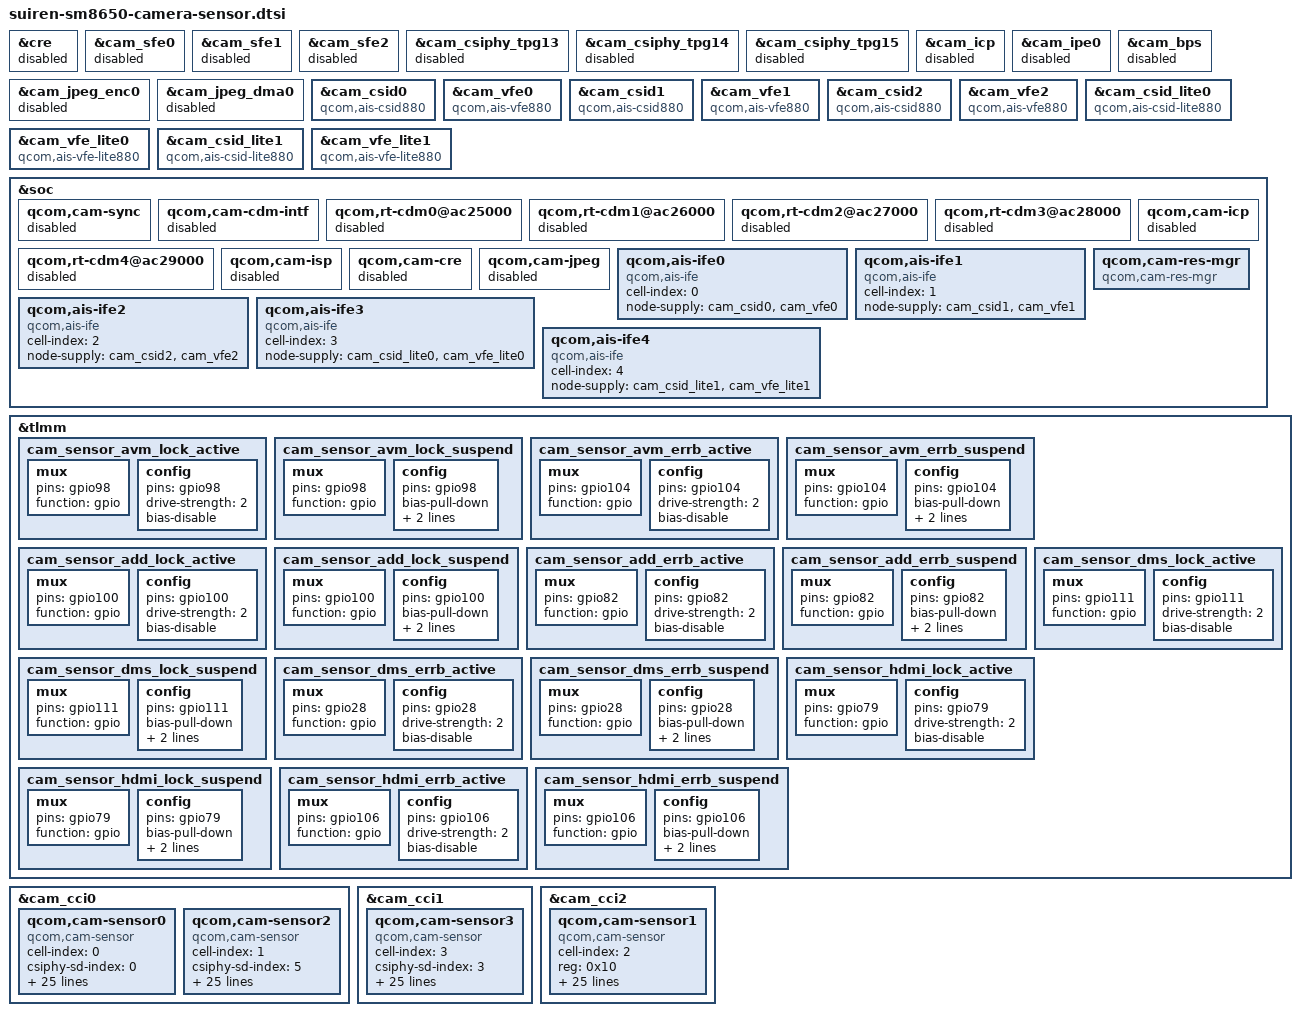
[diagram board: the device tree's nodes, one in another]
#include <dt-bindings/msm-camera.h>

/*Overlay to use AIS and disable unused devices*/
&cre {
	status = "disabled";
};

&cam_sfe0 {
	status = "disabled";
};

&cam_sfe1 {
	status = "disabled";
};

&cam_sfe2 {
	status = "disabled";
};

&cam_csiphy_tpg13 {
	status = "disabled";
};

&cam_csiphy_tpg14 {
	status = "disabled";
};

&cam_csiphy_tpg15 {
	status = "disabled";
};

&cam_icp {
	status = "disabled";
};

&cam_ipe0 {
	status = "disabled";
};

&cam_bps {
	status = "disabled";
};

&cam_jpeg_enc0 {
	status = "disabled";
};

&cam_jpeg_dma0 {
	status = "disabled";
};

&cam_csid0 {
	compatible = "qcom,ais-csid880";
};

&cam_vfe0 {
	compatible = "qcom,ais-vfe880";
};

&cam_csid1 {
	compatible = "qcom,ais-csid880";
};

&cam_vfe1 {
	compatible = "qcom,ais-vfe880";
};

&cam_csid2 {
	compatible = "qcom,ais-csid880";
};

&cam_vfe2 {
	compatible = "qcom,ais-vfe880";
};

&cam_csid_lite0 {
	compatible = "qcom,ais-csid-lite880";
};

&cam_vfe_lite0 {
	compatible = "qcom,ais-vfe-lite880";
};

&cam_csid_lite1 {
	compatible = "qcom,ais-csid-lite880";
};

&cam_vfe_lite1 {
	compatible = "qcom,ais-vfe-lite880";
};

&soc {
	qcom,cam-sync {
		status = "disabled";
	};

	qcom,cam-cdm-intf {
		status = "disabled";
	};

	qcom,rt-cdm0@ac25000 {
		status = "disabled";
	};

	qcom,rt-cdm1@ac26000 {
		status = "disabled";
	};

	qcom,rt-cdm2@ac27000 {
		status = "disabled";
	};

	qcom,rt-cdm3@ac28000 {
		status = "disabled";
	};

	qcom,rt-cdm4@ac29000 {
		status = "disabled";
	};

	qcom,cam-icp {
		status = "disabled";
	};

	qcom,cam-isp {
		status = "disabled";
	};

	qcom,cam-cre {
		status = "disabled";
	};

	qcom,cam-jpeg {
		status = "disabled";
	};

	qcom,ais-ife0 {
		compatible = "qcom,ais-ife";
		cell-index = <0>;
		status = "ok";
		node-supply=<&cam_csid0 &cam_vfe0>;
	};

	qcom,ais-ife1 {
		compatible = "qcom,ais-ife";
		cell-index = <1>;
		status = "ok";
		node-supply=<&cam_csid1 &cam_vfe1>;
	};

	qcom,ais-ife2 {
		compatible = "qcom,ais-ife";
		cell-index = <2>;
		status = "ok";
		node-supply=<&cam_csid2 &cam_vfe2>;
	};

	qcom,ais-ife3 {
		compatible = "qcom,ais-ife";
		cell-index = <3>;
		status = "ok";
		node-supply=<&cam_csid_lite0 &cam_vfe_lite0>;
	};

	qcom,ais-ife4 {
		compatible = "qcom,ais-ife";
		cell-index = <4>;
		status = "ok";
		node-supply=<&cam_csid_lite1 &cam_vfe_lite1>;
	};
};

&tlmm {
//AVM
cam_sensor_avm_lock_active: cam_sensor_avm_lock_active {
	mux {
		pins = "gpio98";
		function = "gpio";
	};

	config {
		pins = "gpio98";
		drive-strength = <2>; /* 2 MA */
		bias-disable;
	};
};

cam_sensor_avm_lock_suspend: cam_sensor_avm_lock_suspend {
	mux {
		pins = "gpio98";
		function = "gpio";
	};

	config {
		pins = "gpio98";
		bias-pull-down; /* PULL DOWN */
		drive-strength = <2>; /* 2 MA */
		output-low;
	};
};

cam_sensor_avm_errb_active: cam_sensor_avm_errb_active {
	mux {
		pins = "gpio104";
		function = "gpio";
	};

	config {
		pins = "gpio104";
		drive-strength = <2>; /* 2 MA */
		bias-disable;
	};
};

cam_sensor_avm_errb_suspend: cam_sensor_avm_errb_suspend {
	mux {
		pins = "gpio104";
		function = "gpio";
	};

	config {
		pins = "gpio104";
		bias-pull-down; /* PULL DOWN */
		drive-strength = <2>; /* 2 MA */
		output-low;
	};
};

//ADD
cam_sensor_add_lock_active: cam_sensor_add_lock_active {
	mux {
		pins = "gpio100";
		function = "gpio";
	};

	config {
		pins = "gpio100";
		drive-strength = <2>; /* 2 MA */
		bias-disable;
	};
};

cam_sensor_add_lock_suspend: cam_sensor_add_lock_suspend {
	mux {
		pins = "gpio100";
		function = "gpio";
	};

	config {
		pins = "gpio100";
		bias-pull-down; /* PULL DOWN */
		drive-strength = <2>; /* 2 MA */
		output-low;
	};
};

cam_sensor_add_errb_active: cam_sensor_add_errb_active {
	mux {
		pins = "gpio82";
		function = "gpio";
	};

	config {
		pins = "gpio82";
		drive-strength = <2>; /* 2 MA */
		bias-disable;
	};
};

cam_sensor_add_errb_suspend: cam_sensor_add_errb_suspend {
	mux {
		pins = "gpio82";
		function = "gpio";
	 };

	config {
		pins = "gpio82";
		bias-pull-down; /* PULL DOWN */
		drive-strength = <2>; /* 2 MA */
		output-low;
	};
};

//DMS
cam_sensor_dms_lock_active: cam_sensor_dms_lock_active {
	mux {
		pins = "gpio111";
		function = "gpio";
	};

	config {
		pins = "gpio111";
		drive-strength = <2>; /* 2 MA */
		bias-disable;
	};
};

cam_sensor_dms_lock_suspend: cam_sensor_dms_lock_suspend {
	mux {
		pins = "gpio111";
		function = "gpio";
	};

	config {
		pins = "gpio111";
		bias-pull-down; /* PULL DOWN */
		drive-strength = <2>; /* 2 MA */
		output-low;
	};
};

cam_sensor_dms_errb_active: cam_sensor_dms_errb_active {
	mux {
		pins = "gpio28";
		function = "gpio";
	};

	config {
		pins = "gpio28";
		drive-strength = <2>; /* 2 MA */
		bias-disable;
	};
};

cam_sensor_dms_errb_suspend: cam_sensor_dms_errb_suspend {
	mux {
		pins = "gpio28";
		function = "gpio";
	};

	config {
		pins = "gpio28";
		bias-pull-down; /* PULL DOWN */
		drive-strength = <2>; /* 2 MA */
		output-low;
	};
};

//HDMI
cam_sensor_hdmi_lock_active: cam_sensor_hdmi_lock_active {
	mux {
		pins = "gpio79";
		function = "gpio";
	};

	config {
		pins = "gpio79";
		drive-strength = <2>; /* 2 MA */
		bias-disable;
	};
};

cam_sensor_hdmi_lock_suspend: cam_sensor_hdmi_lock_suspend {
	mux {
		pins = "gpio79";
		function = "gpio";
	};

	config {
		pins = "gpio79";
		bias-pull-down; /* PULL DOWN */
		drive-strength = <2>; /* 2 MA */
		output-low;
	};
};

cam_sensor_hdmi_errb_active: cam_sensor_hdmi_errb_active {
	mux {
		pins = "gpio106";
		function = "gpio";
	};

	config {
		pins = "gpio106";
		drive-strength = <2>; /* 2 MA */
		bias-disable;
	};
};

cam_sensor_hdmi_errb_suspend: cam_sensor_hdmi_errb_suspend {
	mux {
		pins = "gpio106";
		function = "gpio";
	};

	config {
		pins = "gpio106";
		bias-pull-down; /* PULL DOWN */
		drive-strength = <2>; /* 2 MA */
		output-low;
	};
};
};

&soc {
	qcom,cam-res-mgr {
		compatible = "qcom,cam-res-mgr";
		status = "ok";
	};
};

&cam_cci0 {
	//AVM：96722
	qcom,cam-sensor0 {
		cell-index = <0>;
		compatible = "qcom,cam-sensor";
		csiphy-sd-index = <0>;
		sensor-position-roll = <90>;
		sensor-position-pitch = <0>;
		sensor-position-yaw = <180>;
		cam_clk-supply = <&cam_cc_titan_top_gdsc>;
		regulator-names ="cam_clk";
		rgltr-cntrl-support;
		rgltr-min-voltage = <0>;
		rgltr-max-voltage = <0>;
		rgltr-load-current = <0>;
		gpio-no-mux = <0>;
		pinctrl-names = "cam_default", "cam_suspend";
		pinctrl-0 = <&cam_sensor_avm_lock_active
			&cam_sensor_avm_errb_active>;
		pinctrl-1 = <&cam_sensor_avm_lock_suspend
			&cam_sensor_avm_errb_suspend>;
		sensor-intr-gpios = <&tlmm 98 0>,  <&tlmm 104 0>;
		use-shared-clk;
		gpios = <&tlmm 208 0>;
		gpio-reset = <0>;
		gpio-req-tbl-num = <0>;
		gpio-req-tbl-flags = <0>;
		gpio-req-tbl-label = "CAM_RESET0";
		cci-master = <CCI_MASTER_0>;
		clocks = <&camcc CAM_CC_MCLK0_CLK>;
		clock-names = "cam_clk";
		clock-cntl-level = "nominal";
		clock-rates = <19200000>;
		status = "ok";
	};

	//DMS
	qcom,cam-sensor2 {
		cell-index = <1>;
		compatible = "qcom,cam-sensor";
		csiphy-sd-index = <5>;
		sensor-position-roll = <90>;
		sensor-position-pitch = <0>;
		sensor-position-yaw = <180>;
		cam_clk-supply = <&cam_cc_titan_top_gdsc>;
		regulator-names ="cam_clk";
		rgltr-cntrl-support;
		rgltr-min-voltage = <0>;
		rgltr-max-voltage = <0>;
		rgltr-load-current = <0>;
		gpio-no-mux = <0>;
		pinctrl-names = "cam_default", "cam_suspend";
		pinctrl-0 = <&cam_sensor_dms_lock_active
			&cam_sensor_dms_errb_active>;
		pinctrl-1 = <&cam_sensor_dms_lock_suspend
			&cam_sensor_dms_errb_suspend>;
		sensor-intr-gpios = <&tlmm 111 0>, <&tlmm 28 0>;
		use-shared-clk;
		gpios = <&tlmm 196 0>;
		gpio-reset = <0>;
		gpio-req-tbl-num = <0>;
		gpio-req-tbl-flags = <0>;
		gpio-req-tbl-label = "CAM_RESET1";
		cci-master = <CCI_MASTER_1>;
		clocks = <&camcc CAM_CC_MCLK2_CLK>;
		clock-names = "cam_clk";
		clock-cntl-level = "nominal";
		clock-rates = <19200000>;
		status = "ok";
	};
};

&cam_cci1 {
	//HDMI
	qcom,cam-sensor3 {
		cell-index = <3>;
		compatible = "qcom,cam-sensor";
		csiphy-sd-index = <3>;
		sensor-position-roll = <90>;
		sensor-position-pitch = <0>;
		sensor-position-yaw = <180>;
		cam_clk-supply = <&cam_cc_titan_top_gdsc>;
		regulator-names ="cam_clk";
		rgltr-cntrl-support;
		rgltr-min-voltage = <0>;
		rgltr-max-voltage = <0>;
		rgltr-load-current = <0>;
		gpio-no-mux = <0>;
		pinctrl-names = "cam_default", "cam_suspend";
		pinctrl-0 = <&cam_sensor_hdmi_lock_active
			&cam_sensor_hdmi_errb_active>;
		pinctrl-1 = <&cam_sensor_hdmi_lock_suspend
			&cam_sensor_hdmi_errb_suspend>;
		sensor-intr-gpios = <&tlmm 79 0>, <&tlmm 106 0>;
		use-shared-clk;
		gpios = <&tlmm 199 0>;
		gpio-reset = <0>;
		gpio-req-tbl-num = <0>;
		gpio-req-tbl-flags = <0>;
		gpio-req-tbl-label = "CAM_RESET3";
		cci-master = <CCI_MASTER_0>;
		clocks = <&camcc CAM_CC_MCLK3_CLK>;
		clock-names = "cam_clk";
		clock-cntl-level = "nominal";
		clock-rates = <19200000>;
		status = "ok";
	};
};

&cam_cci2 {
	//AVM:96792
	qcom,cam-sensor1 {
		cell-index = <2>;
		reg = <0x10>;
		compatible = "qcom,cam-sensor";
		csiphy-sd-index = <1>;
		sensor-position-roll = <90>;
		sensor-position-pitch = <0>;
		sensor-position-yaw = <180>;
		cam_clk-supply = <&cam_cc_titan_top_gdsc>;
		regulator-names ="cam_clk";
		rgltr-cntrl-support;
		rgltr-min-voltage = <0>;
		rgltr-max-voltage = <0>;
		rgltr-load-current = <0>;
		pinctrl-names = "cam_default", "cam_suspend";
		pinctrl-0 = <&cam_sensor_add_lock_active
			&cam_sensor_add_errb_active>;
		pinctrl-1 = <&cam_sensor_add_lock_suspend
			&cam_sensor_add_errb_suspend>;
		sensor-intr-gpios = <&tlmm 100 0>, <&tlmm 82 0>;
		use-shared-clk;
		gpios = <&tlmm 162 0>;
		gpio-reset = <0>;
		gpio-req-tbl-num = <0>;
		gpio-req-tbl-flags = <0>;
		gpio-req-tbl-label = "CAM_RESET2";
		cci-master = <CCI_MASTER_1>;
		clocks = <&camcc CAM_CC_MCLK1_CLK>;
		clock-names = "cam_clk";
		clock-cntl-level = "nominal";
		clock-rates = <19200000>;
		status = "ok";
	};
};
